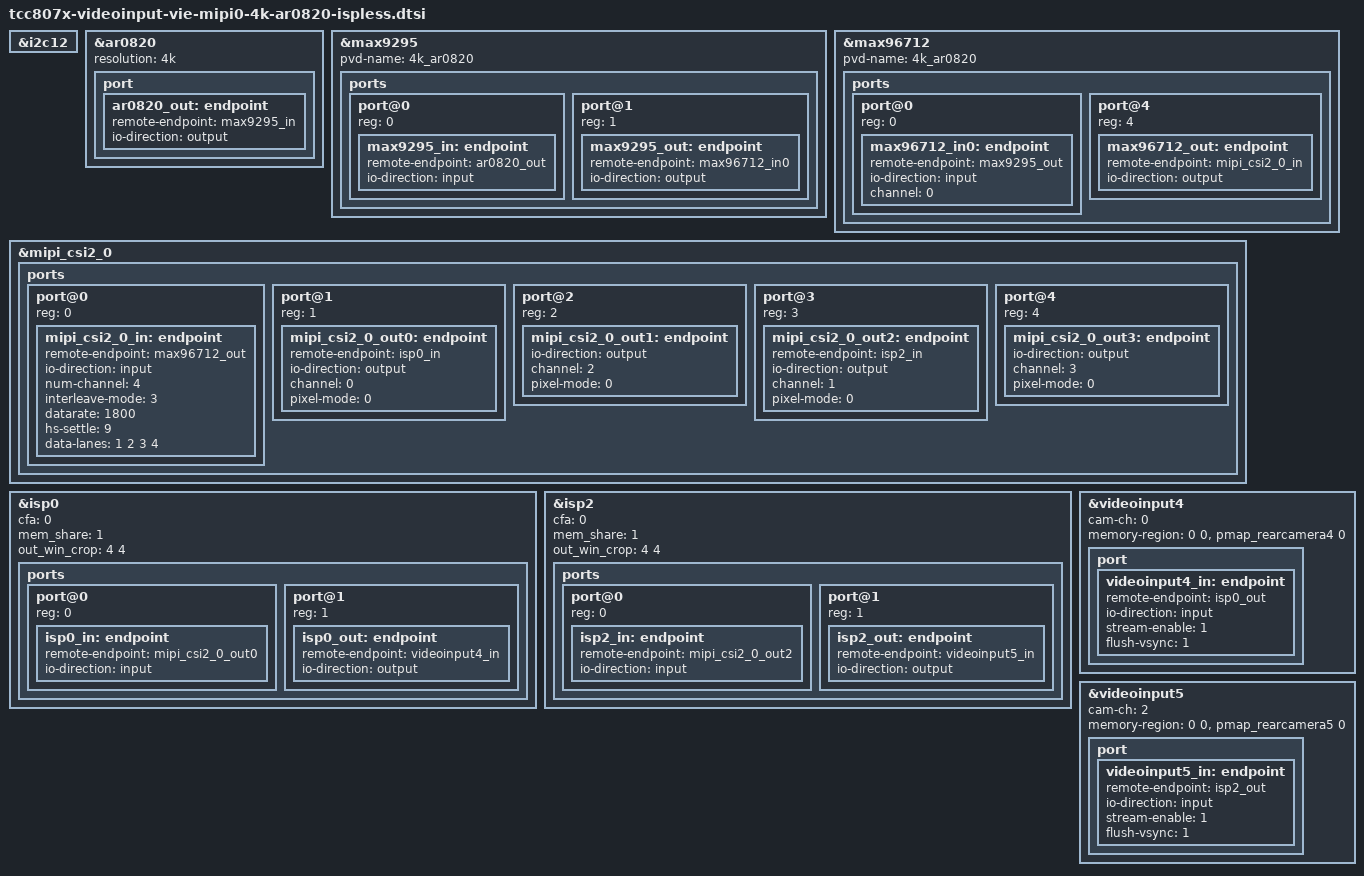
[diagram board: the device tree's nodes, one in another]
// SPDX-License-Identifier: (GPL-2.0-or-later OR MIT)
/*
 * Copyright (C) Telechips Inc.
 */

&i2c12 {
	status = "okay";
};

&ar0820 {
	/* Camera Image Sensor   */
	status		= "okay";
	/* Camera resolution	*/
	/* qhd : 2560 x 1440	*/
	/* 4k  : 3840 x 2160	*/
	resolution	= "4k";

	port {
		ar0820_out: endpoint {
			remote-endpoint = <&max9295_in>;
			io-direction	= "output";
		};
	};
};

&max9295 {
	/* serializer */
	status		= "okay";
	pvd-name	= "4k_ar0820";

	ports {
		#address-cells = <1>;
		#size-cells = <0>;
		port@0 {
			reg = <0>;
			max9295_in: endpoint {
				remote-endpoint = <&ar0820_out>;
				io-direction	= "input";
			};
		};
		port@1 {
			reg = <1>;
			max9295_out: endpoint {
				remote-endpoint = <&max96712_in0>;
				io-direction	= "output";
			};
		};
	};
};

&max96712 {
	/* deserializer */
	status		= "okay";
	pvd-name	= "4k_ar0820";

	ports {
		#address-cells = <1>;
		#size-cells = <0>;
		/*
		 * 0 ~ 3
		 * input ports. The number is matched with VC
		 *
		 * 4
		 * output port.
		 */
		port@0 {
			reg = <0>;
			max96712_in0: endpoint {
				remote-endpoint = <&max9295_out>;
				io-direction	= "input";
				channel		= <0>;
			};
		};
		port@4 {
			reg = <4>;
			max96712_out: endpoint {
				remote-endpoint = <&mipi_csi2_0_in>;
				io-direction	= "output";
			};
		};
	};
};

&mipi_csi2_0 {
	status = "okay";
	ports {
		#address-cells = <1>;
		#size-cells = <0>;
		/*
		 * 0
		 * input port.
		 *
		 * 1 ~ 4
		 * output ports. (1: VC0 ~ 4: VC3)
		 */
		port@0 {
			reg = <0>;
			mipi_csi2_0_in: endpoint {
				remote-endpoint	= <&max96712_out>;
				io-direction	= "input";
				num-channel	= <4>;

				/*
				 * 0: CH0 only, no data interleave
				 * 1: DT only
				 * 2: VC only
				 * 3: VC and DT
				 */
				interleave-mode = <3>;
				/* datarate is clock lane's frequency x 2 */
				datarate = <1800>; /* Mbps */
				hs-settle = <9>;
				data-lanes = <1 2 3 4>;
			};
		};
		port@1 {
			reg = <1>;
			mipi_csi2_0_out0: endpoint {
				remote-endpoint = <&isp0_in>;
				io-direction	= "output";
				channel		= <0>;
				/*
				 * 0: Single pixel mode
				 * 1: Dual pixel mode (RAW8/10/12, YUV422)
				 * 2: Quad pixel mode (RAW8/10/12)
				 * 3: Invalid
				 */
				pixel-mode = <0>;
			};
		};
		port@2 {
			reg = <2>;
			mipi_csi2_0_out1: endpoint {
				io-direction	= "output";
				channel		= <2>;
				pixel-mode = <0>;
			};
		};
		port@3 {
			reg = <3>;
			mipi_csi2_0_out2: endpoint {
				remote-endpoint	= <&isp2_in>;
				io-direction	= "output";
				channel		= <1>;
				pixel-mode = <0>;
			};
		};
		port@4 {
			reg = <4>;
			mipi_csi2_0_out3: endpoint {
				io-direction	= "output";
				channel		= <3>;
				pixel-mode = <0>;
			};
		};
	};
};

&isp0 {
	status = "okay";
	/*
	 * 0: RGGB
	 * 1: NOT used
	 * 2: NOT used
	 * 3: RGBIR (ISP1, 3 only)
	 */
	cfa = <0>;
	mem_share = <1>;

	out_win_crop = <4 4>;

	ports {
		#address-cells = <1>;
		#size-cells = <0>;
		port@0 {
			reg = <0>;
			isp0_in: endpoint {
				remote-endpoint = <&mipi_csi2_0_out0>;
				io-direction	= "input";
			};
		};
		port@1 {
			reg = <1>;
			isp0_out: endpoint {
				remote-endpoint	= <&videoinput4_in>;
				io-direction	= "output";
			};
		};
	};
};

&isp2 {
	status = "okay";
	/*
	 * 0: RGGB
	 * 1: NOT used
	 * 2: NOT used
	 * 3: RGBIR (ISP1, 3 only)
	 */
	cfa = <0>;
	mem_share = <1>;

	out_win_crop = <4 4>;

	ports {
		#address-cells = <1>;
		#size-cells = <0>;
		port@0 {
			reg = <0>;
			isp2_in: endpoint {
				remote-endpoint = <&mipi_csi2_0_out2>;
				io-direction	= "input";
			};
		};
		port@1 {
			reg = <1>;
			isp2_out: endpoint {
				remote-endpoint	= <&videoinput5_in>;
				io-direction	= "output";
			};
		};
	};
};

&videoinput4 {
	status		= "okay";
	cam-ch		= <0>;
	/* memory-region
	 *  - [0]: parking guideline
	 *  - [1]: deinterlacing by viqe
	 *  - [2]: preview
	 *  - [3]: last frame
	 */
	memory-region	= <0
			   0
			   &pmap_rearcamera4
			   0>;
	port {
		videoinput4_in: endpoint {
			remote-endpoint	= <&isp0_out>;
			io-direction	= "input";
			stream-enable	= <1>;	// VIN_CTRL.SE
			flush-vsync	= <1>;	// VIN_MISC.FVS
		};
	};
};

&videoinput5 {
	status		= "okay";
	cam-ch		= <2>;
	/* memory-region
	 *  - [0]: parking guideline
	 *  - [1]: deinterlacing by viqe
	 *  - [2]: preview
	 *  - [3]: last frame
	 */
	memory-region	= <0
			   0
			   &pmap_rearcamera5
			   0>;
	port {
		videoinput5_in: endpoint {
			remote-endpoint	= <&isp2_out>;
			io-direction	= "input";
			stream-enable	= <1>;	// VIN_CTRL.SE
			flush-vsync	= <1>;	// VIN_MISC.FVS
		};
	};
};

